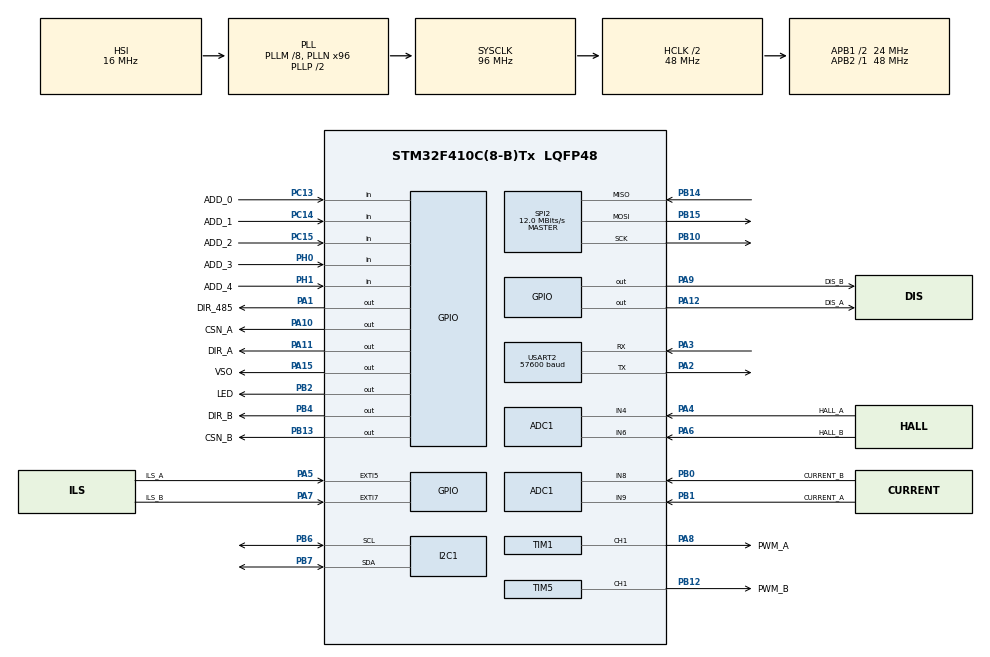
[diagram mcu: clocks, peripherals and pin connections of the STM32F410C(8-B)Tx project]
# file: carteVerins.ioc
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ADC1.Channel-0\#ChannelRegularConversion=ADC_CHANNEL_9
ADC1.Channel-1\#ChannelRegularConversion=ADC_CHANNEL_8
ADC1.Channel-2\#ChannelRegularConversion=ADC_CHANNEL_4
ADC1.Channel-3\#ChannelRegularConversion=ADC_CHANNEL_6
ADC1.Channel-5\#ChannelRegularConversion=ADC_CHANNEL_TEMPSENSOR
ADC1.Channel-6\#ChannelRegularConversion=ADC_CHANNEL_4
ADC1.Channel-7\#ChannelRegularConversion=ADC_CHANNEL_6
ADC1.Channel-8\#ChannelRegularConversion=ADC_CHANNEL_8
ADC1.ClockPrescaler=ADC_CLOCK_SYNC_PCLK_DIV4
ADC1.ContinuousConvMode=ENABLE
ADC1.DMAContinuousRequests=ENABLE
ADC1.EOCSelection=ADC_EOC_SEQ_CONV
ADC1.ExternalTrigConv=ADC_SOFTWARE_START
ADC1.InjNumberOfConversion=0
ADC1.NbrOfConversion=8
ADC1.NbrOfConversionFlag=1
ADC1.Rank-0\#ChannelRegularConversion=1
ADC1.Rank-1\#ChannelRegularConversion=2
ADC1.Rank-2\#ChannelRegularConversion=3
ADC1.Rank-3\#ChannelRegularConversion=4
ADC1.Rank-5\#ChannelRegularConversion=5
ADC1.Rank-6\#ChannelRegularConversion=6
ADC1.Rank-7\#ChannelRegularConversion=7
ADC1.Rank-8\#ChannelRegularConversion=8
ADC1.SamplingTime-0\#ChannelRegularConversion=ADC_SAMPLETIME_112CYCLES
ADC1.SamplingTime-1\#ChannelRegularConversion=ADC_SAMPLETIME_112CYCLES
ADC1.SamplingTime-2\#ChannelRegularConversion=ADC_SAMPLETIME_112CYCLES
ADC1.SamplingTime-3\#ChannelRegularConversion=ADC_SAMPLETIME_112CYCLES
ADC1.SamplingTime-5\#ChannelRegularConversion=ADC_SAMPLETIME_480CYCLES
ADC1.SamplingTime-6\#ChannelRegularConversion=ADC_SAMPLETIME_112CYCLES
ADC1.SamplingTime-7\#ChannelRegularConversion=ADC_SAMPLETIME_112CYCLES
ADC1.SamplingTime-8\#ChannelRegularConversion=ADC_SAMPLETIME_28CYCLES
ADC1.ScanConvMode=ENABLE
ADC1.master=1
ARM.CMSIS.5.6.0.CMSISJjCORE=true
ARM.CMSIS.5.6.0.CMSISJjDSP=Library
Dma.ADC1.2.Direction=DMA_PERIPH_TO_MEMORY
Dma.ADC1.2.FIFOMode=DMA_FIFOMODE_DISABLE
Dma.ADC1.2.Instance=DMA2_Stream0
Dma.ADC1.2.MemDataAlignment=DMA_MDATAALIGN_HALFWORD
Dma.ADC1.2.MemInc=DMA_MINC_ENABLE
Dma.ADC1.2.Mode=DMA_CIRCULAR
Dma.ADC1.2.PeriphDataAlignment=DMA_PDATAALIGN_HALFWORD
Dma.ADC1.2.PeriphInc=DMA_PINC_DISABLE
Dma.ADC1.2.Priority=DMA_PRIORITY_LOW
Dma.I2C1_RX.1.Direction=DMA_PERIPH_TO_MEMORY
Dma.I2C1_RX.1.FIFOMode=DMA_FIFOMODE_DISABLE
Dma.I2C1_RX.1.Instance=DMA1_Stream0
Dma.I2C1_RX.1.MemDataAlignment=DMA_MDATAALIGN_BYTE
Dma.I2C1_RX.1.MemInc=DMA_MINC_ENABLE
Dma.I2C1_RX.1.Mode=DMA_NORMAL
Dma.I2C1_RX.1.PeriphDataAlignment=DMA_PDATAALIGN_BYTE
Dma.I2C1_RX.1.PeriphInc=DMA_PINC_DISABLE
Dma.I2C1_RX.1.Priority=DMA_PRIORITY_LOW
Dma.Request0=USART2_TX
Dma.Request1=I2C1_RX
Dma.Request2=ADC1
Dma.Request3=USART2_RX
Dma.USART2_RX.3.Direction=DMA_PERIPH_TO_MEMORY
Dma.USART2_RX.3.FIFOMode=DMA_FIFOMODE_DISABLE
Dma.USART2_RX.3.Instance=DMA1_Stream5
Dma.USART2_RX.3.MemDataAlignment=DMA_MDATAALIGN_BYTE
Dma.USART2_RX.3.MemInc=DMA_MINC_ENABLE
Dma.USART2_RX.3.Mode=DMA_NORMAL
Dma.USART2_RX.3.PeriphDataAlignment=DMA_PDATAALIGN_BYTE
Dma.USART2_RX.3.PeriphInc=DMA_PINC_DISABLE
Dma.USART2_RX.3.Priority=DMA_PRIORITY_LOW
Dma.USART2_TX.0.Direction=DMA_MEMORY_TO_PERIPH
Dma.USART2_TX.0.FIFOMode=DMA_FIFOMODE_DISABLE
Dma.USART2_TX.0.Instance=DMA1_Stream6
Dma.USART2_TX.0.MemDataAlignment=DMA_MDATAALIGN_BYTE
Dma.USART2_TX.0.MemInc=DMA_MINC_ENABLE
Dma.USART2_TX.0.Mode=DMA_NORMAL
Dma.USART2_TX.0.PeriphDataAlignment=DMA_PDATAALIGN_BYTE
Dma.USART2_TX.0.PeriphInc=DMA_PINC_DISABLE
Dma.USART2_TX.0.Priority=DMA_PRIORITY_LOW
Mcu.Family=STM32F4
Mcu.Name=STM32F410C(8-B)Tx
Mcu.Package=LQFP48
NVIC.DMA1_Stream0_IRQn=true\:0\:0\:false\:false\:true\:false\:true
NVIC.DMA1_Stream5_IRQn=true\:0\:0\:false\:false\:true\:false\:true
NVIC.DMA1_Stream6_IRQn=true\:0\:0\:false\:false\:true\:false\:true
NVIC.DMA2_Stream0_IRQn=true\:0\:0\:false\:false\:true\:false\:true
NVIC.EXTI9_5_IRQn=true\:0\:0\:false\:false\:true\:true\:true
NVIC.PriorityGroup=NVIC_PRIORITYGROUP_4
NVIC.SPI2_IRQn=true\:0\:0\:false\:false\:true\:true\:true
NVIC.TIM1_TRG_COM_TIM11_IRQn=true\:0\:0\:false\:false\:true\:true\:true
NVIC.USART2_IRQn=true\:0\:0\:false\:false\:true\:true\:true
PA0-WKUP.GPIO_Label=SYS_WAKEUP
PA0-WKUP.Mode=SYS_WakeUp0
PA0-WKUP.Signal=SYS_WKUP1
PA1.GPIO_Label=DIR_485
PA1.Signal=GPIO_Output
PA10.GPIO_Label=CSN_A
PA10.Signal=GPIO_Output
PA11.GPIO_Label=DIR_A
PA11.Signal=GPIO_Output
PA12.GPIO_Label=DIS_A
PA12.Signal=GPIO_Output
PA13.Mode=Trace_Asynchronous_SW
PA13.Signal=SYS_JTMS-SWDIO
PA14.Mode=Trace_Asynchronous_SW
PA14.Signal=SYS_JTCK-SWCLK
PA15.GPIO_Label=VSO
PA15.Signal=GPIO_Output
PA2.Mode=Asynchronous
PA2.Signal=USART2_TX
PA3.Mode=Asynchronous
PA3.Signal=USART2_RX
PA4.GPIO_Label=HALL_A
PA4.Signal=ADCx_IN4
PA5.GPIO_Label=ILS_A
PA5.Signal=GPXTI5
PA6.GPIO_Label=HALL_B
PA6.Signal=ADCx_IN6
PA7.GPIO_Label=ILS_B
PA7.GPIO_PuPd=GPIO_PULLUP
PA7.Signal=GPXTI7
PA8.GPIO_Label=PWM_A
PA8.Signal=S_TIM1_CH1
PA9.GPIO_Label=DIS_B
PA9.Signal=GPIO_Output
PB0.GPIO_Label=CURRENT_B
PB0.Signal=ADCx_IN8
PB1.GPIO_Label=CURRENT_A
PB1.Signal=ADCx_IN9
PB10.Mode=Full_Duplex_Master
PB10.Signal=SPI2_SCK
PB12.GPIO_Label=PWM_B
PB12.Signal=S_TIM5_CH1
PB13.GPIO_Label=CSN_B
PB13.Signal=GPIO_Output
PB14.Mode=Full_Duplex_Master
PB14.Signal=SPI2_MISO
PB15.Mode=Full_Duplex_Master
PB15.Signal=SPI2_MOSI
PB2.GPIO_Label=LED
PB2.GPIO_ModeDefaultOutputPP=GPIO_MODE_OUTPUT_PP
PB2.GPIO_Speed=GPIO_SPEED_FREQ_LOW
PB2.Signal=GPIO_Output
PB3.Mode=Trace_Asynchronous_SW
PB3.Signal=SYS_JTDO-SWO
PB4.GPIO_Label=DIR_B
PB4.Signal=GPIO_Output
PB6.Mode=I2C
PB6.Signal=I2C1_SCL
PB7.Mode=I2C
PB7.Signal=I2C1_SDA
PC13-ANTI_TAMP.GPIO_Label=ADD_0
PC13-ANTI_TAMP.GPIO_PuPd=GPIO_PULLUP
PC13-ANTI_TAMP.Signal=GPIO_Input
PC14-OSC32_IN.GPIO_Label=ADD_1
PC14-OSC32_IN.GPIO_PuPd=GPIO_PULLUP
PC14-OSC32_IN.Signal=GPIO_Input
PC15-OSC32_OUT.GPIO_Label=ADD_2
PC15-OSC32_OUT.GPIO_PuPd=GPIO_PULLUP
PC15-OSC32_OUT.Signal=GPIO_Input
PH0\ -\ OSC_IN.GPIO_Label=ADD_3
PH0\ -\ OSC_IN.GPIO_PuPd=GPIO_PULLUP
PH0\ -\ OSC_IN.Signal=GPIO_Input
PH1\ -\ OSC_OUT.GPIO_Label=ADD_4
PH1\ -\ OSC_OUT.GPIO_PuPd=GPIO_PULLUP
PH1\ -\ OSC_OUT.Signal=GPIO_Input
ProjectManager.HeapSize=0x200
ProjectManager.StackSize=0x400
ProjectManager.TargetToolchain=STM32CubeIDE
RCC.48MHZClocksFreq_Value=48000000
RCC.AHBCLKDivider=RCC_SYSCLK_DIV2
RCC.AHBFreq_Value=48000000
RCC.APB1CLKDivider=RCC_HCLK_DIV2
RCC.APB1Freq_Value=24000000
RCC.APB1TimFreq_Value=48000000
RCC.APB2Freq_Value=48000000
RCC.APB2TimFreq_Value=48000000
RCC.CortexFreq_Value=48000000
RCC.HCLKFreq_Value=48000000
RCC.HSE_VALUE=25000000
RCC.HSI_VALUE=16000000
RCC.LSE_VALUE=32768
RCC.PLLM=8
RCC.PLLN=96
RCC.SYSCLKFreq_VALUE=96000000
RCC.SYSCLKSource=RCC_SYSCLKSOURCE_PLLCLK
RCC.VCOOutputFreq_Value=192000000
SH.ADCx_IN4.0=ADC1_IN4,IN4
SH.ADCx_IN6.0=ADC1_IN6,IN6
SH.ADCx_IN8.0=ADC1_IN8,IN8
SH.ADCx_IN9.0=ADC1_IN9,IN9
SH.S_TIM1_CH1.0=TIM1_CH1,PWM Generation1 CH1
SH.S_TIM5_CH1.0=TIM5_CH1,PWM Generation1 CH1
SPI2.BaudRatePrescaler=SPI_BAUDRATEPRESCALER_2
SPI2.CalculateBaudRate=12.0 MBits/s
SPI2.Direction=SPI_DIRECTION_2LINES
SPI2.Mode=SPI_MODE_MASTER
SPI2.VirtualType=VM_MASTER
STMicroelectronics.X-CUBE-MEMS1.8.2.0.STM32IiMotionFXIiLibraryCcSensorsJjSTM32IiMotionFXIiLibraryJjCore=true
TIM1.Channel-PWM\ Generation1\ CH1=TIM_CHANNEL_1
TIM1.Period=200-1
TIM1.Prescaler=12-1
TIM1.TIM_MasterOutputTrigger=TIM_TRGO_RESET
TIM11.Period=10000-1
TIM11.Prescaler=48-1
TIM5.Channel-PWM\ Generation1\ CH1=TIM_CHANNEL_1
TIM5.Period=200-1
TIM5.Prescaler=12-1
TIM9.Channel-Output\ Compare1\ No\ Output=TIM_CHANNEL_1
USART2.BaudRate=57600
USART2.VirtualMode=VM_ASYNC
VP_ADC1_TempSens_Input.Mode=IN-TempSens
VP_ARM.CMSIS_VS_CMSISJjCORE_5.3.0_5.6.0.Mode=CMSISJjCORE
VP_ARM.CMSIS_VS_CMSISJjDSP_1.7.0_5.6.0.Mode=CMSISJjDSP
VP_CRC_VS_CRC.Mode=CRC_Activate
VP_STMicroelectronics.X-CUBE-MEMS1_VS_SensorsJjSTM32IiMotionFXIiLibrary_2.4.1_8.2.0.Mode=SensorsJjSTM32IiMotionFXIiLibrary
VP_TIM11_VS_ClockSourceINT.Mode=Enable_Timer
VP_TIM1_VS_ClockSourceINT.Mode=Internal
VP_TIM9_VS_ClockSourceINT.Mode=Internal
VP_TIM9_VS_no_output1.Mode=Output Compare1 No Output
board=custom

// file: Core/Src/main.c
/* USER CODE BEGIN Header */
/**
 ******************************************************************************
 * @file           : main.c
 * @brief          : Main program body
 ******************************************************************************
 * @attention
 *
 * <h2><center>&copy; Copyright (c) 2020 STMicroelectronics.
 * All rights reserved.</center></h2>
 *
 * This software component is licensed by ST under Ultimate Liberty license
 * SLA0044, the "License"; You may not use this file except in compliance with
 * the License. You may obtain a copy of the License at:
 *                             www.st.com/SLA0044
 *
 ******************************************************************************
 */
/* USER CODE END Header */
#include "main.h"

/* USER CODE BEGIN Includes */
#include "application.h"

/* USER CODE END Includes */

ADC_HandleTypeDef hadc1;
DMA_HandleTypeDef hdma_adc1;

CRC_HandleTypeDef hcrc;

I2C_HandleTypeDef hi2c1;
DMA_HandleTypeDef hdma_i2c1_rx;

SPI_HandleTypeDef hspi2;

TIM_HandleTypeDef htim1;
TIM_HandleTypeDef htim5;
TIM_HandleTypeDef htim9;
TIM_HandleTypeDef htim11;

UART_HandleTypeDef huart2;
DMA_HandleTypeDef hdma_usart2_tx;
DMA_HandleTypeDef hdma_usart2_rx;

void SystemClock_Config(void);
static void MX_GPIO_Init(void);
static void MX_DMA_Init(void);
static void MX_ADC1_Init(void);
static void MX_I2C1_Init(void);
static void MX_SPI2_Init(void);
static void MX_TIM1_Init(void);
static void MX_TIM5_Init(void);
static void MX_USART2_UART_Init(void);
static void MX_CRC_Init(void);
static void MX_TIM9_Init(void);
static void MX_TIM11_Init(void);

/* USER CODE BEGIN 0 */
int _write (int file, char *ptr, int len)
{
  int i;
  for (i = 0; i < len; i++)
    ITM_SendChar (*ptr++);
  return len;
}

/* USER CODE END 0 */

int main(void)
{

  /* MCU Configuration--------------------------------------------------------*/

  /* Reset of all peripherals, Initializes the Flash interface and the Systick. */
  HAL_Init();

  /* Configure the system clock */
  SystemClock_Config();

  /* Initialize all configured peripherals */
  MX_GPIO_Init();
  MX_DMA_Init();
  MX_ADC1_Init();
  MX_I2C1_Init();
  MX_SPI2_Init();
  MX_TIM1_Init();
  MX_TIM5_Init();
  MX_USART2_UART_Init();
  MX_CRC_Init();
  MX_TIM9_Init();
  MX_TIM11_Init();

  /* Infinite loop */
  /* USER CODE BEGIN WHILE */
  application ();
  while (1)
    {
    /* USER CODE END WHILE */

    }
}

void SystemClock_Config(void)
{
  RCC_OscInitTypeDef RCC_OscInitStruct = {0};
  RCC_ClkInitTypeDef RCC_ClkInitStruct = {0};

  /** Configure the main internal regulator output voltage
  */
  __HAL_RCC_PWR_CLK_ENABLE();
  __HAL_PWR_VOLTAGESCALING_CONFIG(PWR_REGULATOR_VOLTAGE_SCALE1);
  /** Initializes the RCC Oscillators according to the specified parameters
  * in the RCC_OscInitTypeDef structure.
  */
  RCC_OscInitStruct.OscillatorType = RCC_OSCILLATORTYPE_HSI;
  RCC_OscInitStruct.HSIState = RCC_HSI_ON;
  RCC_OscInitStruct.HSICalibrationValue = RCC_HSICALIBRATION_DEFAULT;
  RCC_OscInitStruct.PLL.PLLState = RCC_PLL_ON;
  RCC_OscInitStruct.PLL.PLLSource = RCC_PLLSOURCE_HSI;
  RCC_OscInitStruct.PLL.PLLM = 8;
  RCC_OscInitStruct.PLL.PLLN = 96;
  RCC_OscInitStruct.PLL.PLLP = RCC_PLLP_DIV2;
  RCC_OscInitStruct.PLL.PLLQ = 4;
  RCC_OscInitStruct.PLL.PLLR = 2;
  if (HAL_RCC_OscConfig(&RCC_OscInitStruct) != HAL_OK)
  {
    Error_Handler();
  }
  /** Initializes the CPU, AHB and APB buses clocks
  */
  RCC_ClkInitStruct.ClockType = RCC_CLOCKTYPE_HCLK|RCC_CLOCKTYPE_SYSCLK
                              |RCC_CLOCKTYPE_PCLK1|RCC_CLOCKTYPE_PCLK2;
  RCC_ClkInitStruct.SYSCLKSource = RCC_SYSCLKSOURCE_PLLCLK;
  RCC_ClkInitStruct.AHBCLKDivider = RCC_SYSCLK_DIV2;
  RCC_ClkInitStruct.APB1CLKDivider = RCC_HCLK_DIV2;
  RCC_ClkInitStruct.APB2CLKDivider = RCC_HCLK_DIV1;

  if (HAL_RCC_ClockConfig(&RCC_ClkInitStruct, FLASH_LATENCY_1) != HAL_OK)
  {
    Error_Handler();
  }
}

static void MX_ADC1_Init(void)
{

  ADC_ChannelConfTypeDef sConfig = {0};

  /** Configure the global features of the ADC (Clock, Resolution, Data Alignment and number of conversion)
  */
  hadc1.Instance = ADC1;
  hadc1.Init.ClockPrescaler = ADC_CLOCK_SYNC_PCLK_DIV4;
  hadc1.Init.Resolution = ADC_RESOLUTION_12B;
  hadc1.Init.ScanConvMode = ENABLE;
  hadc1.Init.ContinuousConvMode = ENABLE;
  hadc1.Init.DiscontinuousConvMode = DISABLE;
  hadc1.Init.ExternalTrigConvEdge = ADC_EXTERNALTRIGCONVEDGE_NONE;
  hadc1.Init.ExternalTrigConv = ADC_SOFTWARE_START;
  hadc1.Init.DataAlign = ADC_DATAALIGN_RIGHT;
  hadc1.Init.NbrOfConversion = 8;
  hadc1.Init.DMAContinuousRequests = ENABLE;
  hadc1.Init.EOCSelection = ADC_EOC_SEQ_CONV;
  if (HAL_ADC_Init(&hadc1) != HAL_OK)
  {
    Error_Handler();
  }
  /** Configure for the selected ADC regular channel its corresponding rank in the sequencer and its sample time.
  */
  sConfig.Channel = ADC_CHANNEL_9;
  sConfig.Rank = 1;
  sConfig.SamplingTime = ADC_SAMPLETIME_112CYCLES;
  if (HAL_ADC_ConfigChannel(&hadc1, &sConfig) != HAL_OK)
  {
    Error_Handler();
  }
  /** Configure for the selected ADC regular channel its corresponding rank in the sequencer and its sample time.
  */
  sConfig.Channel = ADC_CHANNEL_8;
  sConfig.Rank = 2;
  if (HAL_ADC_ConfigChannel(&hadc1, &sConfig) != HAL_OK)
  {
    Error_Handler();
  }
  /** Configure for the selected ADC regular channel its corresponding rank in the sequencer and its sample time.
  */
  sConfig.Channel = ADC_CHANNEL_4;
  sConfig.Rank = 3;
  if (HAL_ADC_ConfigChannel(&hadc1, &sConfig) != HAL_OK)
  {
    Error_Handler();
  }
  /** Configure for the selected ADC regular channel its corresponding rank in the sequencer and its sample time.
  */
  sConfig.Channel = ADC_CHANNEL_6;
  sConfig.Rank = 4;
  if (HAL_ADC_ConfigChannel(&hadc1, &sConfig) != HAL_OK)
  {
    Error_Handler();
  }
  /** Configure for the selected ADC regular channel its corresponding rank in the sequencer and its sample time.
  */
  sConfig.Channel = ADC_CHANNEL_TEMPSENSOR;
  sConfig.Rank = 5;
  sConfig.SamplingTime = ADC_SAMPLETIME_480CYCLES;
  if (HAL_ADC_ConfigChannel(&hadc1, &sConfig) != HAL_OK)
  {
    Error_Handler();
  }
  /** Configure for the selected ADC regular channel its corresponding rank in the sequencer and its sample time.
  */
  sConfig.Channel = ADC_CHANNEL_4;
  sConfig.Rank = 6;
  sConfig.SamplingTime = ADC_SAMPLETIME_112CYCLES;
  if (HAL_ADC_ConfigChannel(&hadc1, &sConfig) != HAL_OK)
  {
    Error_Handler();
  }
  /** Configure for the selected ADC regular channel its corresponding rank in the sequencer and its sample time.
  */
  sConfig.Channel = ADC_CHANNEL_6;
  sConfig.Rank = 7;
  if (HAL_ADC_ConfigChannel(&hadc1, &sConfig) != HAL_OK)
  {
    Error_Handler();
  }
  /** Configure for the selected ADC regular channel its corresponding rank in the sequencer and its sample time.
  */
  sConfig.Channel = ADC_CHANNEL_8;
  sConfig.Rank = 8;
  sConfig.SamplingTime = ADC_SAMPLETIME_28CYCLES;
  if (HAL_ADC_ConfigChannel(&hadc1, &sConfig) != HAL_OK)
  {
    Error_Handler();
  }

}

static void MX_CRC_Init(void)
{

  hcrc.Instance = CRC;
  if (HAL_CRC_Init(&hcrc) != HAL_OK)
  {
    Error_Handler();
  }

}

static void MX_I2C1_Init(void)
{

  hi2c1.Instance = I2C1;
  hi2c1.Init.ClockSpeed = 100000;
  hi2c1.Init.DutyCycle = I2C_DUTYCYCLE_2;
  hi2c1.Init.OwnAddress1 = 0;
  hi2c1.Init.AddressingMode = I2C_ADDRESSINGMODE_7BIT;
  hi2c1.Init.DualAddressMode = I2C_DUALADDRESS_DISABLE;
  hi2c1.Init.OwnAddress2 = 0;
  hi2c1.Init.GeneralCallMode = I2C_GENERALCALL_DISABLE;
  hi2c1.Init.NoStretchMode = I2C_NOSTRETCH_DISABLE;
  if (HAL_I2C_Init(&hi2c1) != HAL_OK)
  {
    Error_Handler();
  }

}

static void MX_SPI2_Init(void)
{

  /* SPI2 parameter configuration*/
  hspi2.Instance = SPI2;
  hspi2.Init.Mode = SPI_MODE_MASTER;
  hspi2.Init.Direction = SPI_DIRECTION_2LINES;
  hspi2.Init.DataSize = SPI_DATASIZE_8BIT;
  hspi2.Init.CLKPolarity = SPI_POLARITY_LOW;
  hspi2.Init.CLKPhase = SPI_PHASE_1EDGE;
  hspi2.Init.NSS = SPI_NSS_SOFT;
  hspi2.Init.BaudRatePrescaler = SPI_BAUDRATEPRESCALER_2;
  hspi2.Init.FirstBit = SPI_FIRSTBIT_MSB;
  hspi2.Init.TIMode = SPI_TIMODE_DISABLE;
  hspi2.Init.CRCCalculation = SPI_CRCCALCULATION_DISABLE;
  hspi2.Init.CRCPolynomial = 15;
  if (HAL_SPI_Init(&hspi2) != HAL_OK)
  {
    Error_Handler();
  }

}

static void MX_TIM1_Init(void)
{

  TIM_ClockConfigTypeDef sClockSourceConfig = {0};
  TIM_MasterConfigTypeDef sMasterConfig = {0};
  TIM_OC_InitTypeDef sConfigOC = {0};
  TIM_BreakDeadTimeConfigTypeDef sBreakDeadTimeConfig = {0};

  htim1.Instance = TIM1;
  htim1.Init.Prescaler = 12-1;
  htim1.Init.CounterMode = TIM_COUNTERMODE_UP;
  htim1.Init.Period = 200-1;
  htim1.Init.ClockDivision = TIM_CLOCKDIVISION_DIV1;
  htim1.Init.RepetitionCounter = 0;
  htim1.Init.AutoReloadPreload = TIM_AUTORELOAD_PRELOAD_DISABLE;
  if (HAL_TIM_Base_Init(&htim1) != HAL_OK)
  {
    Error_Handler();
  }
  sClockSourceConfig.ClockSource = TIM_CLOCKSOURCE_INTERNAL;
  if (HAL_TIM_ConfigClockSource(&htim1, &sClockSourceConfig) != HAL_OK)
  {
    Error_Handler();
  }
  if (HAL_TIM_PWM_Init(&htim1) != HAL_OK)
  {
    Error_Handler();
  }
  sMasterConfig.MasterOutputTrigger = TIM_TRGO_RESET;
  sMasterConfig.MasterSlaveMode = TIM_MASTERSLAVEMODE_DISABLE;
  if (HAL_TIMEx_MasterConfigSynchronization(&htim1, &sMasterConfig) != HAL_OK)
  {
    Error_Handler();
  }
  sConfigOC.OCMode = TIM_OCMODE_PWM1;
  sConfigOC.Pulse = 0;
  sConfigOC.OCPolarity = TIM_OCPOLARITY_HIGH;
  sConfigOC.OCNPolarity = TIM_OCNPOLARITY_HIGH;
  sConfigOC.OCFastMode = TIM_OCFAST_DISABLE;
  sConfigOC.OCIdleState = TIM_OCIDLESTATE_RESET;
  sConfigOC.OCNIdleState = TIM_OCNIDLESTATE_RESET;
  if (HAL_TIM_PWM_ConfigChannel(&htim1, &sConfigOC, TIM_CHANNEL_1) != HAL_OK)
  {
    Error_Handler();
  }
  sBreakDeadTimeConfig.OffStateRunMode = TIM_OSSR_DISABLE;
  sBreakDeadTimeConfig.OffStateIDLEMode = TIM_OSSI_DISABLE;
  sBreakDeadTimeConfig.LockLevel = TIM_LOCKLEVEL_OFF;
  sBreakDeadTimeConfig.DeadTime = 0;
  sBreakDeadTimeConfig.BreakState = TIM_BREAK_DISABLE;
  sBreakDeadTimeConfig.BreakPolarity = TIM_BREAKPOLARITY_HIGH;
  sBreakDeadTimeConfig.AutomaticOutput = TIM_AUTOMATICOUTPUT_DISABLE;
  if (HAL_TIMEx_ConfigBreakDeadTime(&htim1, &sBreakDeadTimeConfig) != HAL_OK)
  {
    Error_Handler();
  }
  HAL_TIM_MspPostInit(&htim1);

}

static void MX_TIM5_Init(void)
{

  TIM_MasterConfigTypeDef sMasterConfig = {0};
  TIM_OC_InitTypeDef sConfigOC = {0};

  htim5.Instance = TIM5;
  htim5.Init.Prescaler = 12-1;
  htim5.Init.CounterMode = TIM_COUNTERMODE_UP;
  htim5.Init.Period = 200-1;
  htim5.Init.ClockDivision = TIM_CLOCKDIVISION_DIV1;
  htim5.Init.AutoReloadPreload = TIM_AUTORELOAD_PRELOAD_DISABLE;
  if (HAL_TIM_PWM_Init(&htim5) != HAL_OK)
  {
    Error_Handler();
  }
  sMasterConfig.MasterOutputTrigger = TIM_TRGO_RESET;
  sMasterConfig.MasterSlaveMode = TIM_MASTERSLAVEMODE_DISABLE;
  if (HAL_TIMEx_MasterConfigSynchronization(&htim5, &sMasterConfig) != HAL_OK)
  {
    Error_Handler();
  }
  sConfigOC.OCMode = TIM_OCMODE_PWM1;
  sConfigOC.Pulse = 0;
  sConfigOC.OCPolarity = TIM_OCPOLARITY_HIGH;
  sConfigOC.OCFastMode = TIM_OCFAST_DISABLE;
  if (HAL_TIM_PWM_ConfigChannel(&htim5, &sConfigOC, TIM_CHANNEL_1) != HAL_OK)
  {
    Error_Handler();
  }
  HAL_TIM_MspPostInit(&htim5);

}

static void MX_TIM9_Init(void)
{

  TIM_ClockConfigTypeDef sClockSourceConfig = {0};
  TIM_OC_InitTypeDef sConfigOC = {0};

  htim9.Instance = TIM9;
  htim9.Init.Prescaler = 0;
  htim9.Init.CounterMode = TIM_COUNTERMODE_UP;
  htim9.Init.Period = 65535;
  htim9.Init.ClockDivision = TIM_CLOCKDIVISION_DIV1;
  htim9.Init.AutoReloadPreload = TIM_AUTORELOAD_PRELOAD_DISABLE;
  if (HAL_TIM_Base_Init(&htim9) != HAL_OK)
  {
    Error_Handler();
  }
  sClockSourceConfig.ClockSource = TIM_CLOCKSOURCE_INTERNAL;
  if (HAL_TIM_ConfigClockSource(&htim9, &sClockSourceConfig) != HAL_OK)
  {
    Error_Handler();
  }
  if (HAL_TIM_OC_Init(&htim9) != HAL_OK)
  {
    Error_Handler();
  }
  sConfigOC.OCMode = TIM_OCMODE_TIMING;
  sConfigOC.Pulse = 0;
  sConfigOC.OCPolarity = TIM_OCPOLARITY_HIGH;
  sConfigOC.OCFastMode = TIM_OCFAST_DISABLE;
  if (HAL_TIM_OC_ConfigChannel(&htim9, &sConfigOC, TIM_CHANNEL_1) != HAL_OK)
  {
    Error_Handler();
  }

}

static void MX_TIM11_Init(void)
{

  htim11.Instance = TIM11;
  htim11.Init.Prescaler = 48-1;
  htim11.Init.CounterMode = TIM_COUNTERMODE_UP;
  htim11.Init.Period = 10000-1;
  htim11.Init.ClockDivision = TIM_CLOCKDIVISION_DIV1;
  htim11.Init.AutoReloadPreload = TIM_AUTORELOAD_PRELOAD_DISABLE;
  if (HAL_TIM_Base_Init(&htim11) != HAL_OK)
  {
    Error_Handler();
  }

}

static void MX_USART2_UART_Init(void)
{

  huart2.Instance = USART2;
  huart2.Init.BaudRate = 57600;
  huart2.Init.WordLength = UART_WORDLENGTH_8B;
  huart2.Init.StopBits = UART_STOPBITS_1;
  huart2.Init.Parity = UART_PARITY_NONE;
  huart2.Init.Mode = UART_MODE_TX_RX;
  huart2.Init.HwFlowCtl = UART_HWCONTROL_NONE;
  huart2.Init.OverSampling = UART_OVERSAMPLING_16;
  if (HAL_UART_Init(&huart2) != HAL_OK)
  {
    Error_Handler();
  }

}

static void MX_DMA_Init(void)
{

  /* DMA controller clock enable */
  __HAL_RCC_DMA1_CLK_ENABLE();
  __HAL_RCC_DMA2_CLK_ENABLE();

  /* DMA interrupt init */
  /* DMA1_Stream0_IRQn interrupt configuration */
  HAL_NVIC_SetPriority(DMA1_Stream0_IRQn, 0, 0);
  HAL_NVIC_EnableIRQ(DMA1_Stream0_IRQn);
  /* DMA1_Stream5_IRQn interrupt configuration */
  HAL_NVIC_SetPriority(DMA1_Stream5_IRQn, 0, 0);
  HAL_NVIC_EnableIRQ(DMA1_Stream5_IRQn);
  /* DMA1_Stream6_IRQn interrupt configuration */
  HAL_NVIC_SetPriority(DMA1_Stream6_IRQn, 0, 0);
  HAL_NVIC_EnableIRQ(DMA1_Stream6_IRQn);
  /* DMA2_Stream0_IRQn interrupt configuration */
  HAL_NVIC_SetPriority(DMA2_Stream0_IRQn, 0, 0);
  HAL_NVIC_EnableIRQ(DMA2_Stream0_IRQn);

}

static void MX_GPIO_Init(void)
{
  GPIO_InitTypeDef GPIO_InitStruct = {0};

  /* GPIO Ports Clock Enable */
  __HAL_RCC_GPIOC_CLK_ENABLE();
  __HAL_RCC_GPIOH_CLK_ENABLE();
  __HAL_RCC_GPIOA_CLK_ENABLE();
  __HAL_RCC_GPIOB_CLK_ENABLE();

  /*Configure GPIO pin Output Level */
  HAL_GPIO_WritePin(GPIOA, DIR_485_Pin|DIS_B_Pin|CSN_A_Pin|DIR_A_Pin
                          |DIS_A_Pin|VSO_Pin, GPIO_PIN_RESET);

  /*Configure GPIO pin Output Level */
  HAL_GPIO_WritePin(GPIOB, LED_Pin|CSN_B_Pin|DIR_B_Pin, GPIO_PIN_RESET);

  /*Configure GPIO pins : ADD_0_Pin ADD_1_Pin ADD_2_Pin */
  GPIO_InitStruct.Pin = ADD_0_Pin|ADD_1_Pin|ADD_2_Pin;
  GPIO_InitStruct.Mode = GPIO_MODE_INPUT;
  GPIO_InitStruct.Pull = GPIO_PULLUP;
  HAL_GPIO_Init(GPIOC, &GPIO_InitStruct);

  /*Configure GPIO pins : ADD_3_Pin ADD_4_Pin */
  GPIO_InitStruct.Pin = ADD_3_Pin|ADD_4_Pin;
  GPIO_InitStruct.Mode = GPIO_MODE_INPUT;
  GPIO_InitStruct.Pull = GPIO_PULLUP;
  HAL_GPIO_Init(GPIOH, &GPIO_InitStruct);

  /*Configure GPIO pins : DIR_485_Pin DIS_B_Pin CSN_A_Pin DIR_A_Pin
                           DIS_A_Pin VSO_Pin */
  GPIO_InitStruct.Pin = DIR_485_Pin|DIS_B_Pin|CSN_A_Pin|DIR_A_Pin
                          |DIS_A_Pin|VSO_Pin;
  GPIO_InitStruct.Mode = GPIO_MODE_OUTPUT_PP;
  GPIO_InitStruct.Pull = GPIO_NOPULL;
  GPIO_InitStruct.Speed = GPIO_SPEED_FREQ_LOW;
  HAL_GPIO_Init(GPIOA, &GPIO_InitStruct);

  /*Configure GPIO pin : ILS_A_Pin */
  GPIO_InitStruct.Pin = ILS_A_Pin;
  GPIO_InitStruct.Mode = GPIO_MODE_IT_RISING;
  GPIO_InitStruct.Pull = GPIO_NOPULL;
  HAL_GPIO_Init(ILS_A_GPIO_Port, &GPIO_InitStruct);

  /*Configure GPIO pin : ILS_B_Pin */
  GPIO_InitStruct.Pin = ILS_B_Pin;
  GPIO_InitStruct.Mode = GPIO_MODE_IT_RISING;
  GPIO_InitStruct.Pull = GPIO_PULLUP;
  HAL_GPIO_Init(ILS_B_GPIO_Port, &GPIO_InitStruct);

  /*Configure GPIO pins : LED_Pin CSN_B_Pin DIR_B_Pin */
  GPIO_InitStruct.Pin = LED_Pin|CSN_B_Pin|DIR_B_Pin;
  GPIO_InitStruct.Mode = GPIO_MODE_OUTPUT_PP;
  GPIO_InitStruct.Pull = GPIO_NOPULL;
  GPIO_InitStruct.Speed = GPIO_SPEED_FREQ_LOW;
  HAL_GPIO_Init(GPIOB, &GPIO_InitStruct);

  /* EXTI interrupt init*/
  HAL_NVIC_SetPriority(EXTI9_5_IRQn, 0, 0);
  HAL_NVIC_EnableIRQ(EXTI9_5_IRQn);

}

void Error_Handler(void)
{
}

/************************ (C) COPYRIGHT STMicroelectronics *****END OF FILE****/
